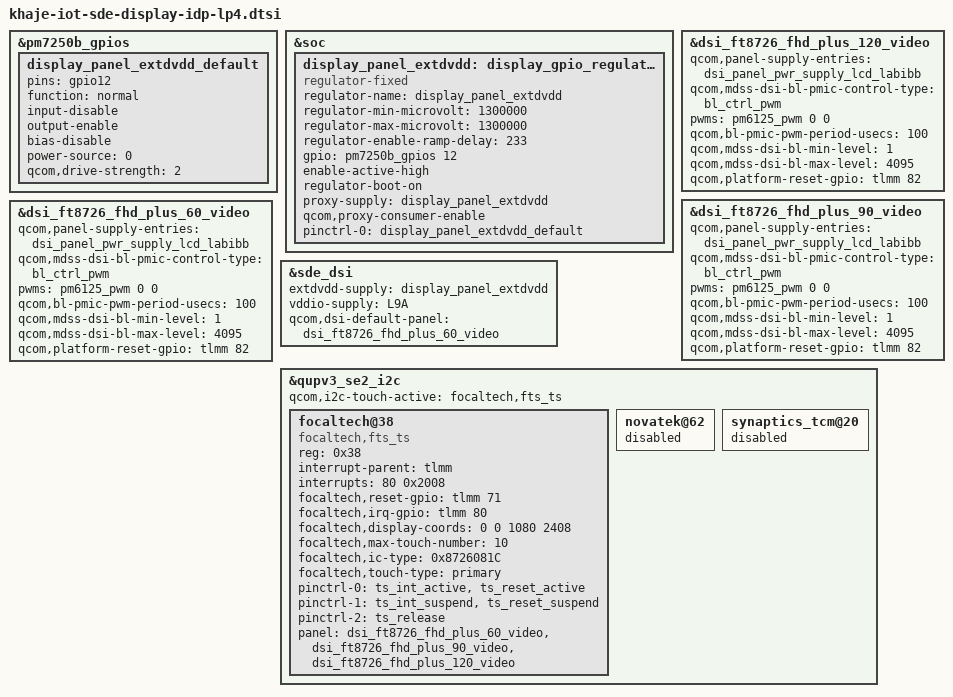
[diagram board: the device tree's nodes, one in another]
// SPDX-License-Identifier: BSD-3-Clause
/*
 * Copyright (c) Qualcomm Technologies, Inc. and/or its subsidiaries.
 */

#include "khaje-sde-display-idp.dtsi"

&pm7250b_gpios {
	display_panel_extdvdd_default: display_panel_extdvdd_default {
		pins = "gpio12";
		function = "normal";
		input-disable;
		output-enable;
		bias-disable;
		power-source = <0>;
		qcom,drive-strength = <2>;
	};
};

&soc {
	display_panel_extdvdd: display_gpio_regulator@2 {
		compatible = "regulator-fixed";
		regulator-name = "display_panel_extdvdd";
		regulator-min-microvolt = <1300000>;
		regulator-max-microvolt = <1300000>;
		regulator-enable-ramp-delay = <233>;
		gpio = <&pm7250b_gpios 12 0>;
		enable-active-high;
		regulator-boot-on;
		proxy-supply = <&display_panel_extdvdd>;
		qcom,proxy-consumer-enable;
		pinctrl-names = "default";
		pinctrl-0 = <&display_panel_extdvdd_default>;
	};
};

&dsi_ft8726_fhd_plus_120_video {
	qcom,panel-supply-entries = <&dsi_panel_pwr_supply_lcd_labibb>;
	qcom,mdss-dsi-bl-pmic-control-type = "bl_ctrl_pwm";
	pwms = <&pm6125_pwm 0 0>;
	qcom,bl-pmic-pwm-period-usecs = <100>;
	qcom,mdss-dsi-bl-min-level = <1>;
	qcom,mdss-dsi-bl-max-level = <4095>;
	qcom,platform-reset-gpio = <&tlmm 82 0>;
	/delete-property/ qcom,esd-check-enabled;
};

&dsi_ft8726_fhd_plus_90_video {
	qcom,panel-supply-entries = <&dsi_panel_pwr_supply_lcd_labibb>;
	qcom,mdss-dsi-bl-pmic-control-type = "bl_ctrl_pwm";
	pwms = <&pm6125_pwm 0 0>;
	qcom,bl-pmic-pwm-period-usecs = <100>;
	qcom,mdss-dsi-bl-min-level = <1>;
	qcom,mdss-dsi-bl-max-level = <4095>;
	qcom,platform-reset-gpio = <&tlmm 82 0>;
	/delete-property/ qcom,esd-check-enabled;
};

&dsi_ft8726_fhd_plus_60_video {
	qcom,panel-supply-entries = <&dsi_panel_pwr_supply_lcd_labibb>;
	qcom,mdss-dsi-bl-pmic-control-type = "bl_ctrl_pwm";
	pwms = <&pm6125_pwm 0 0>;
	qcom,bl-pmic-pwm-period-usecs = <100>;
	qcom,mdss-dsi-bl-min-level = <1>;
	qcom,mdss-dsi-bl-max-level = <4095>;
	qcom,platform-reset-gpio = <&tlmm 82 0>;
	/delete-property/ qcom,esd-check-enabled;
};

&sde_dsi {
	extdvdd-supply = <&display_panel_extdvdd>;
	vddio-supply = <&L9A>;
	qcom,dsi-default-panel = <&dsi_ft8726_fhd_plus_60_video>;
};

&qupv3_se2_i2c {
        status = "okay";
        qcom,i2c-touch-active= "focaltech,fts_ts";

                focaltech@38 {
                status = "okay";
                compatible = "focaltech,fts_ts";
                reg = <0x38>;

                interrupt-parent = <&tlmm>;
                interrupts = <80 0x2008>;
                focaltech,reset-gpio = <&tlmm 71 0x00>;
                focaltech,irq-gpio = <&tlmm 80 0x2008>;
                focaltech,display-coords = <0 0 1080 2408>;
                focaltech,max-touch-number = <10>;
                focaltech,ic-type = <0x8726081C>;
                focaltech,touch-type = "primary";

                pinctrl-names = "pmx_ts_active","pmx_ts_suspend",
                        "pmx_ts_release";
                pinctrl-0 = <&ts_int_active &ts_reset_active>;
                pinctrl-1 = <&ts_int_suspend &ts_reset_suspend>;
                pinctrl-2 = <&ts_release>;
		panel = <&dsi_ft8726_fhd_plus_60_video
			&dsi_ft8726_fhd_plus_90_video
			&dsi_ft8726_fhd_plus_120_video>;
        };


        novatek@62 {
                status = "disabled";
        };

        synaptics_tcm@20 {
                status = "disabled";
        };
};
